# STM32H503 register map
File version: 1.5
CPU: CM33 r0p0, little endian, MPU, FPU, 4 interrupt priority bits
Registers are 32-bit, read-write, reset 0x0 unless marked. A register's access mark holds for its fields unless they carry their own. Offsets are from the block's base; [hi:lo] are bit positions.

## CRC — Cyclic redundancy check calculation unit
Base 0x40023000
0x00 CRC_DR reset 0xFFFFFFFF — CRC data register
  [31:0] DR — Data register bits This register is used to write new data to the CRC calculator. It holds the previous CRC calculation result when it is read. If the data size is less than 32 bits, the least significant bits are used to write/read the correct value.
0x04 CRC_IDR — CRC independent data register
  [31:0] IDR — General-purpose 32-bit data register bits These bits can be used as a temporary storage location for four bytes. This register is not affected by CRC resets generated by the RESET bit in the CRC_CR register
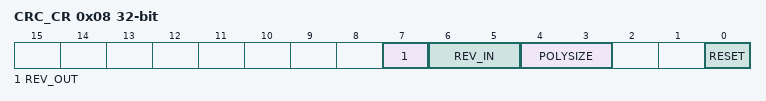
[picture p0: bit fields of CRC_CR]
0x08 CRC_CR — CRC control register
  [7] REV_OUT — Reverse output data This bit controls the reversal of the bit order of the output data.
    0=Bit order not affected; 1=Bit-reversed output format
  [6:5] REV_IN — Reverse input data These bits control the reversal of the bit order of the input data
    0=Bit order not affected; 1=Bit reversal done by byte; 2=Bit reversal done by half-word; 3=Bit reversal done by word
  [4:3] POLYSIZE — Polynomial size These bits control the size of the polynomial.
    0=32 bit polynomial; 1=16 bit polynomial; 2=8 bit polynomial; 3=7 bit polynomial
  [0] RESET — RESET bit This bit is set by software to reset the CRC calculation unit and set the data register to the value stored in the CRC_INIT register. This bit can only be set, it is automatically cleared by hardware
0x10 CRC_INIT reset 0xFFFFFFFF — CRC initial value
  [31:0] CRC_INIT — Programmable initial CRC value This register is used to write the CRC initial value.
0x14 CRC_POL reset 0x4C11DB7 — CRC polynomial
  [31:0] POL — Programmable polynomial This register is used to write the coefficients of the polynomial to be used for CRC calculation. If the polynomial size is less than 32 bits, the least significant bits have to be used to program the correct value.

## ICACHE — Instruction cache
Base 0x40030400
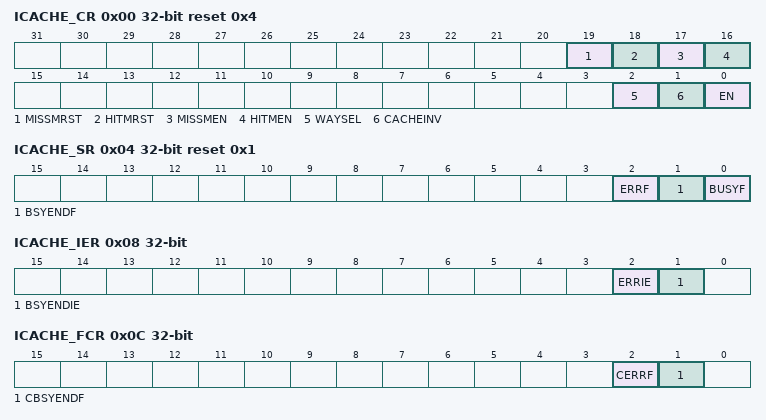
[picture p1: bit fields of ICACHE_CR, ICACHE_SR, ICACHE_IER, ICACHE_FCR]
0x00 ICACHE_CR access per field reset 0x4 — ICACHE control register
  [19] MISSMRST rw — miss monitor reset
    0=no effect; 1=reset cache miss monitor
  [18] HITMRST rw — hit monitor reset
    0=no effect; 1=reset cache hit monitor
  [17] MISSMEN rw — miss monitor enable
    0=cache miss monitor switched off. Stopping the monitor does not reset it.; 1=cache miss monitor enabled
  [16] HITMEN rw — hit monitor enable
    0=cache hit monitor switched off. Stopping the monitor does not reset it.; 1=cache hit monitor enabled
  [2] WAYSEL rw — cache associativity mode selection This bit allows user to choose ICACHE set-associativity. It can be written by software only when cache is disabled (EN = 0).
    0=direct mapped cache (1-way cache); 1=n-way set associative cache (reset value)
  [1] CACHEINV wo — cache invalidation Set by software and cleared by hardware when the BUSYF flag is set (during cache maintenance operation). Writing 0 has no effect.
    0=no effect; 1=invalidate entire cache (all cache lines valid bit = 0)
  [0] EN rw — enable
    0=cache disabled; 1=cache enabled
0x04 ICACHE_SR ro reset 0x1 — ICACHE status register
  [2] ERRF — cache error flag
    0=no error; 1=an error occurred during the operation (cacheable write)
  [1] BSYENDF — busy end flag
    0=cache busy; 1=full invalidate CACHEINV operation finished
  [0] BUSYF — busy flag
    0=cache not busy on a CACHEINV operation; 1=cache executing a full invalidate CACHEINV operation
0x08 ICACHE_IER — ICACHE interrupt enable register
  [2] ERRIE — interrupt enable on cache error Set by software to enable an interrupt generation in case of cache functional error (cacheable write access)
    0=interrupt disabled on error; 1=interrupt enabled on error
  [1] BSYENDIE — interrupt enable on busy end Set by software to enable an interrupt generation at the end of a cache invalidate operation.
    0=interrupt disabled on busy end; 1=interrupt enabled on busy end
0x0C ICACHE_FCR wo — ICACHE flag clear register
  [2] CERRF — clear cache error flag Set by software.
    0=no effect; 1=clears ERRF flag in ICACHE_SR
  [1] CBSYENDF — clear busy end flag Set by software.
    0=no effect; 1=clears BSYENDF flag in ICACHE_SR
0x10 ICACHE_HMONR ro — ICACHE hit monitor register
  [31:0] HITMON — cache hit monitor counter
0x14 ICACHE_MMONR ro — ICACHE miss monitor register
  [15:0] MISSMON — cache miss monitor counter

## WWDG — System window watchdog
Base 0x40002C00
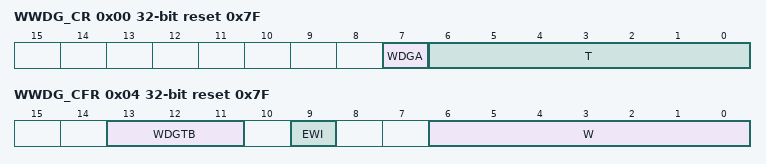
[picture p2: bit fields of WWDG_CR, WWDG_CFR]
0x00 WWDG_CR reset 0x7F — WWDG control register
  [7] WDGA — Activation bit This bit is set by software and only cleared by hardware after a reset. When WDGA = 1, the watchdog can generate a reset.
    0=Watchdog disabled; 1=Watchdog enabled
  [6:0] T — 7-bit counter (MSB to LSB) These bits contain the value of the watchdog counter, decremented every (4096 x 2WDGTB[2:0]) PCLK cycles. A reset is produced when it is decremented from 0x40 to 0x3F (T6 becomes cleared).
0x04 WWDG_CFR reset 0x7F — WWDG configuration register
  [13:11] WDGTB — Timer base The timebase of the prescaler can be modified as follows:
    0=CK counter clock (PCLK div 4096) div 1; 1=CK counter clock (PCLK div 4096) div 2; 2=CK counter clock (PCLK div 4096) div 4; 3=CK counter clock (PCLK div 4096) div 8; 4=CK counter clock (PCLK div 4096) div 16; 5=CK counter clock (PCLK div 4096) div 32; 6=CK counter clock (PCLK div 4096) div 64; 7=CK counter clock (PCLK div 4096) div 128
  [9] EWI — Early wakeup interrupt When set, an interrupt occurs whenever the counter reaches the value 0x40. This interrupt is only cleared by hardware after a reset.
  [6:0] W — 7-bit window value These bits contain the window value to be compared with the down-counter.
0x08 WWDG_SR — WWDG status register
  [0] EWIF — Early wakeup interrupt flag This bit is set by hardware when the counter has reached the value 0x40. It must be cleared by software by writing '0'. Writing '1' has no effect. This bit is also set if the interrupt is not enabled.
